# CC26x0 register map
File version: 2.3
CPU: CM3 r2p1, little endian, no MPU, no FPU, 0x3 interrupt priority bits, 0x0 interrupts
Registers are 32-bit, read-write, reset 0x0 unless marked. A register's access mark holds for its fields unless they carry their own. Offsets are from the block's base; [hi:lo] are bit positions; {n}, {i} and the like mark numbered series; 'fields as' and 'values as' point back to an identical list.

## I2S0 — I2S Audio DMA module supporting formats I2S, LJF, RJF and DSP
Base 0x40021000
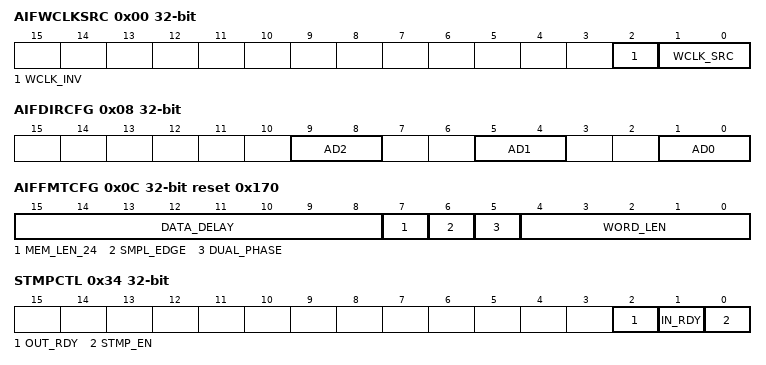
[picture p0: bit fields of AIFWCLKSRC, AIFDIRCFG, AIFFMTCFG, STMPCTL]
0x00 AIFWCLKSRC — WCLK Source Selection
  [2] WCLK_INV, [1:0] WCLK_SRC
0x04 AIFDMACFG — DMA Buffer Size Configuration
  [7:0] END_FRAME_IDX
0x08 AIFDIRCFG — Pin Direction
  [9:8] AD2, [5:4] AD1, [1:0] AD0
0x0C AIFFMTCFG reset 0x170 — Serial Interface Format Configuration
  [15:8] DATA_DELAY, [7] MEM_LEN_24, [6] SMPL_EDGE, [5] DUAL_PHASE, [4:0] WORD_LEN
{0x10+4i} AIFWMASK{i} reset 0x3 (i=0..2) — Word Selection Bit Mask for Pin {i}
  [7:0] MASK
0x1C AIFPWMVALUE — Audio Interface PWM Debug Value
  [15:0] PULSE_WIDTH
0x20 AIFINPTRNEXT — DMA Input Buffer Next Pointer
  [31:0] PTR
0x24 AIFINPTR — DMA Input Buffer Current Pointer
  [31:0] PTR
0x28 AIFOUTPTRNEXT — DMA Output Buffer Next Pointer
  [31:0] PTR
0x2C AIFOUTPTR — DMA Output Buffer Current Pointer
  [31:0] PTR
0x34 STMPCTL — SampleStaMP Generator Control Register
  [2] OUT_RDY, [1] IN_RDY, [0] STMP_EN
0x38 STMPXCNTCAPT0 ro — Captured XOSC Counter Value, Capture Channel 0
  [15:0] CAPT_VALUE
0x3C STMPXPER ro — XOSC Period Value
  [15:0] VALUE
0x40 STMPWCNTCAPT0 ro — Captured WCLK Counter Value, Capture Channel 0
  [15:0] CAPT_VALUE
0x44 STMPWPER — WCLK Counter Period Value
  [15:0] VALUE
0x48 STMPINTRIG — WCLK Counter Trigger Value for Input Pins
  [15:0] IN_START_WCNT
0x4C STMPOUTTRIG — WCLK Counter Trigger Value for Output Pins
  [15:0] OUT_START_WCNT
0x50 STMPWSET — WCLK Counter Set Operation
  [15:0] VALUE
0x54 STMPWADD — WCLK Counter Add Operation
  [15:0] VALUE_INC
0x58 STMPXPERMIN reset 0xFFFF — XOSC Minimum Period Value Minimum Value of STMPXPER
  [15:0] VALUE
0x5C STMPWCNT ro — Current Value of WCNT
  [15:0] CURR_VALUE
0x60 STMPXCNT ro — Current Value of XCNT
  [15:0] CURR_VALUE
0x64 STMPXCNTCAPT1 ro — Captured XOSC Counter Value, Capture Channel 1
  [15:0] CAPT_VALUE
0x68 STMPWCNTCAPT1 ro — Captured WCLK Counter Value, Capture Channel 1
  [15:0] CAPT_VALUE
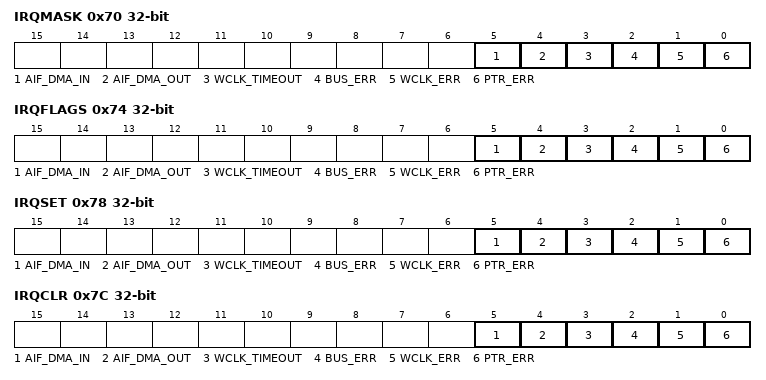
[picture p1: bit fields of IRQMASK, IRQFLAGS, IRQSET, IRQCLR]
0x70 IRQMASK — Masked Interrupt Status Register
  [5] AIF_DMA_IN, [4] AIF_DMA_OUT, [3] WCLK_TIMEOUT, [2] BUS_ERR, [1] WCLK_ERR, [0] PTR_ERR
0x74 IRQFLAGS ro — Raw Interrupt Status Register
  fields as IRQMASK
0x78 IRQSET wo — Interrupt Set Register
  fields as IRQMASK
0x7C IRQCLR wo — Interrupt Clear Register
  fields as IRQMASK

## IOC — IO Controller (IOC) - configures all the DIOs and resides in the MCU domain.
Base 0x40081000
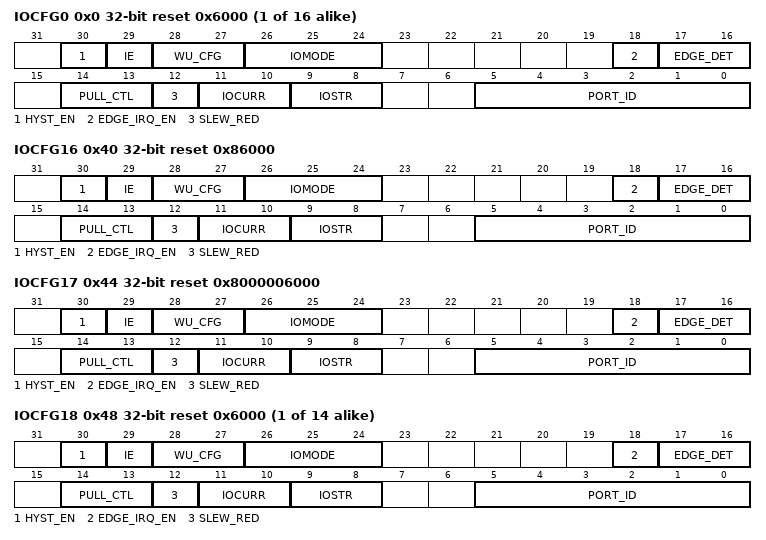
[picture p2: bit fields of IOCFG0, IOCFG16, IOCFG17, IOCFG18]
{0x0+4i} IOCFG{i} reset 0x6000 (i=0..15) — Configuration of DIO{i}
  [30] HYST_EN, [29] IE, [28:27] WU_CFG, [26:24] IOMODE, [18] EDGE_IRQ_EN, [17:16] EDGE_DET, [14:13] PULL_CTL, [12] SLEW_RED, [11:10] IOCURR, [9:8] IOSTR, [5:0] PORT_ID
0x40 IOCFG16 reset 0x86000 — Configuration of DIO16
  fields as IOCFG0
0x44 IOCFG17 reset 0x8000006000 — Configuration of DIO17
  fields as IOCFG0
{0x0+4i} IOCFG{i} reset 0x6000 (i=18..31) — Configuration of DIO{i}
  fields as IOCFG0

## RFC_DBELL — RF Core Doorbell
Base 0x40041000
0x00 CMDR — Doorbell Command Register
  [31:0] CMD
0x04 CMDSTA ro — Doorbell Command Status Register
  [31:0] STAT
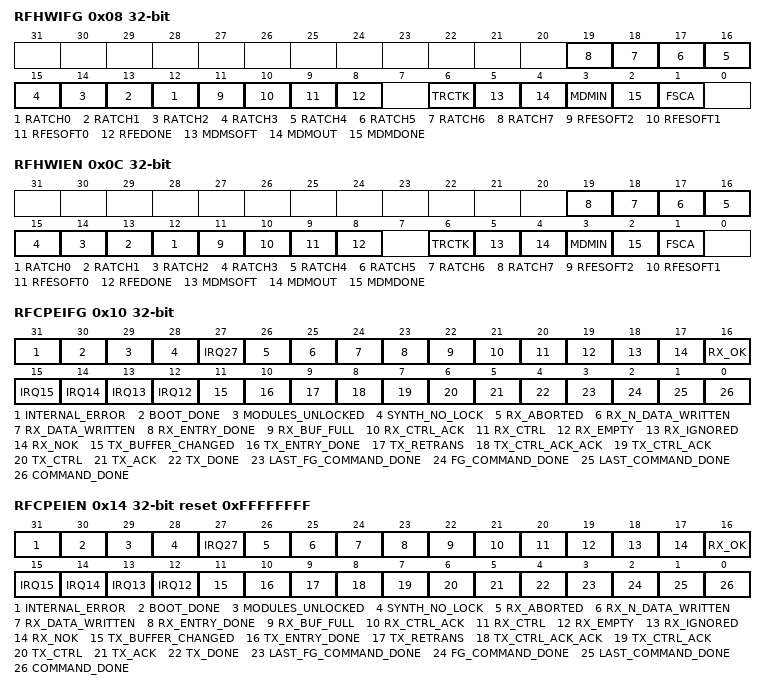
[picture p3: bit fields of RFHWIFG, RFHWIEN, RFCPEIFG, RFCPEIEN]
0x08 RFHWIFG — Interrupt Flags From RF Hardware Modules
  [n+12] RATCH{n} (n=0..7), [11] RFESOFT2, [10] RFESOFT1, [9] RFESOFT0, [8] RFEDONE, [6] TRCTK, [5] MDMSOFT, [4] MDMOUT, [3] MDMIN, [2] MDMDONE, [1] FSCA
0x0C RFHWIEN — Interrupt Enable For RF Hardware Modules
  fields as RFHWIFG
0x10 RFCPEIFG — Interrupt Flags For Command and Packet Engine Generated Interrupts
  [31] INTERNAL_ERROR, [30] BOOT_DONE, [29] MODULES_UNLOCKED, [28] SYNTH_NO_LOCK, [27] IRQ27, [26] RX_ABORTED, [25] RX_N_DATA_WRITTEN, [24] RX_DATA_WRITTEN, [23] RX_ENTRY_DONE, [22] RX_BUF_FULL, [21] RX_CTRL_ACK, [20] RX_CTRL, [19] RX_EMPTY, [18] RX_IGNORED, [17] RX_NOK, [16] RX_OK, [n] IRQ{n} (n=12..15), [11] TX_BUFFER_CHANGED, [10] TX_ENTRY_DONE, [9] TX_RETRANS, [8] TX_CTRL_ACK_ACK, [7] TX_CTRL_ACK, [6] TX_CTRL, [5] TX_ACK, [4] TX_DONE, [3] LAST_FG_COMMAND_DONE, [2] FG_COMMAND_DONE, [1] LAST_COMMAND_DONE, [0] COMMAND_DONE
0x14 RFCPEIEN reset 0xFFFFFFFF — Interrupt Enable For Command and Packet Engine Generated Interrupts
  fields as RFCPEIFG
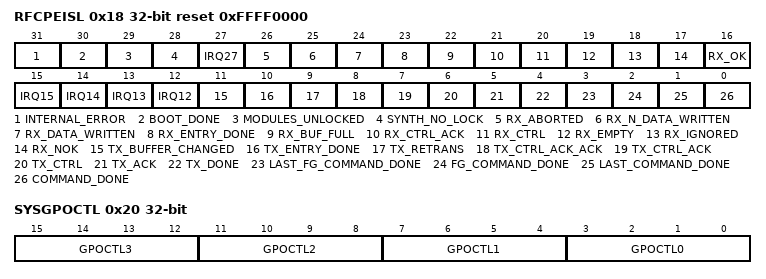
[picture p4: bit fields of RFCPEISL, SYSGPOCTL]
0x18 RFCPEISL reset 0xFFFF0000 — Interrupt Vector Selection For Command and Packet Engine Generated Interrupts
  fields as RFCPEIFG
0x1C RFACKIFG — Doorbell Command Acknowledgement Interrupt Flag
  [0] ACKFLAG
0x20 SYSGPOCTL — RF Core General Purpose Output Control
  [4n+3:4n] GPOCTL{n} (n=0..3)
